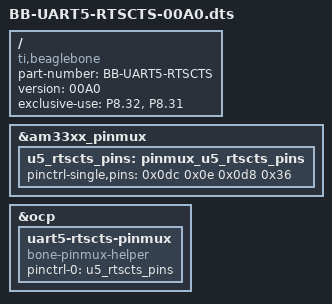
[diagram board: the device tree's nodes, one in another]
/* BB-UART5-RTSCTS-00A0.dts
 * Written by Alexander Hiam <hiamalexander@gmail.com>
 * for Logic Supply - http://logicsupply.com
 * Jan 28, 2014
 *
 * This overlay enables RTS/CTS flow control for UART5.
 * HDMI must be disabled before enabling this overlay, see:
 *  http://www.logicsupply.com/blog/2013/07/18/disabling-the-beaglebone-black-hdmi-cape/
 *
 * Copyright (c) 2014 - Logic Supply (http://logicsupply.com)
 * This program is free software; you can redistribute it and/or modify
 * it under the terms of the GNU General Public License version 2 as
 * published by the Free Software Foundation.
 */

/dts-v1/;
/plugin/;

/{
  compatible = "ti,beaglebone", "ti,beaglebone-black";

  part-number = "BB-UART5-RTSCTS";
  version = "00A0";

  exclusive-use =
  "P8.32", /* uart5 rts */
  "P8.31"; /* uart5 cts */

  fragment@0 {
    /* Sets pinmux for flow control pins. */
    target = <&am33xx_pinmux>;
    __overlay__ {
      u5_rtscts_pins: pinmux_u5_rtscts_pins {
        pinctrl-single,pins = <
          0x0dc 0x0e /* uart5_rtsn - pullup | mode 6 (uart5_rtsn) */
          0x0d8 0x36 /* uart5_ctsn - rx enable | pullup | mode 6 (uart5_ctsn) */
        >;
      };
    };
  };

  fragment@1 {
    /* Enable pinmux-helper driver for setting mux configuration. */
    target = <&ocp>; /* On-Chip Peripherals */
    __overlay__ {
      uart5-rtscts-pinmux {
        compatible = "bone-pinmux-helper"; /* Use the pinmux helper */
        status="okay";
        /* Define custom names for indexes in pinctrl array: */
        pinctrl-names = "default";
        /* Set the elements of the pinctrl array to the pinmux overlays
           defined above: */
        pinctrl-0 = <&u5_rtscts_pins>;
      };
    };
  };
};
